# CH32M030 register map
Vendor: WCH Ltd.; File version: 1.1
Registers are 32-bit, read-write, reset 0x0 unless marked. A register's access mark holds for its fields unless they carry their own. Offsets are from the block's base; [hi:lo] are bit positions.

## WWDG — Window watchdog
Base 0x40002C00
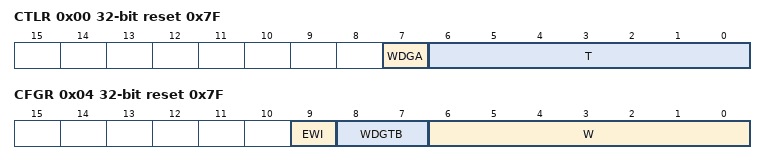
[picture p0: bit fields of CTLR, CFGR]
0x00 CTLR reset 0x7F — Control register (WWDG_CR)
  [7] WDGA — Activation bit
  [6:0] T — 7-bit counter (MSB to LSB)
0x04 CFGR reset 0x7F — Configuration register (WWDG_CFR)
  [9] EWI — Early Wakeup Interrupt
  [8:7] WDGTB — Timer Base
  [6:0] W — 7-bit window value
0x08 STATR — Status register (WWDG_SR)
  [0] EWIF — Early Wakeup Interrupt Flag

## TIM3 — Streamlined Timer
Base 0x40000400
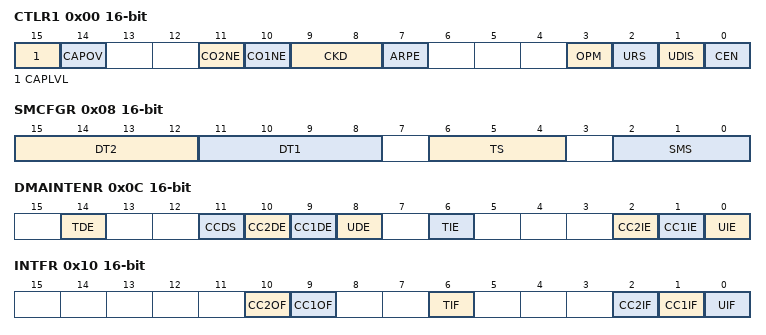
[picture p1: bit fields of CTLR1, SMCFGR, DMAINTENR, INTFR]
0x00 CTLR1 16-bit — control register 1
  [15] CAPLVL — Timer capture level indication enable
  [14] CAPOV — Timer capture value configuration enable
  [11] CO2NE — complementary output with dead zone enabled
  [10] CO1NE — complementary output with dead zone enabled
  [9:8] CKD — Clock division
  [7] ARPE — Auto-reload preload enable
  [3] OPM — One-pulse mode
  [2] URS — Update request source
  [1] UDIS — Update disable
  [0] CEN — Counter enable
0x08 SMCFGR 16-bit — slave mode control register
  [15:12] DT2 — TIMER3 channel2 dead-time setting
  [11:8] DT1 — TIMER3 channel1 dead-time setting
  [6:4] TS — Trigger selection
  [2:0] SMS — Slave mode selection
0x0C DMAINTENR 16-bit — DMA/Interrupt enable register
  [14] TDE — Trigger DMA request enable
  [11] CCDS — Capture/compare DMA selection
  [10] CC2DE — Capture/Compare 2 DMA request enable
  [9] CC1DE — Capture/Compare 1 DMA request enable
  [8] UDE — Update DMA request enable
  [6] TIE — Trigger interrupt enable
  [2] CC2IE — Capture/Compare 2 interrupt enable
  [1] CC1IE — Capture/Compare 1 interrupt enable
  [0] UIE — Update interrupt enable
0x10 INTFR 16-bit — status register
  [10] CC2OF — Capture/compare 2 overcapture flag
  [9] CC1OF — Capture/Compare 1 overcapture flag
  [6] TIF — Trigger interrupt flag
  [2] CC2IF — Capture/Compare 2 interrupt flag
  [1] CC1IF — Capture/compare 1 interrupt flag
  [0] UIF — Update interrupt flag
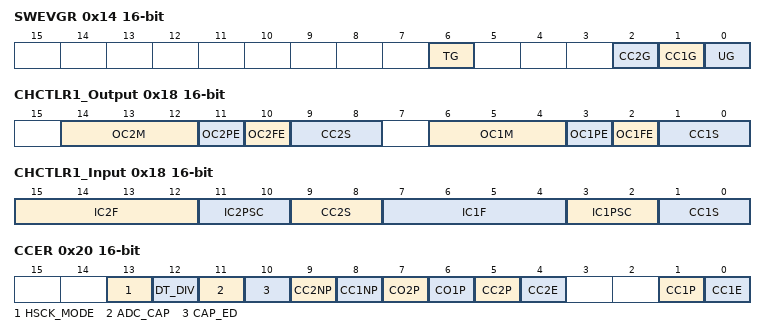
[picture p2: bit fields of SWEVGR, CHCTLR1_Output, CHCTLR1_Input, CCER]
0x14 SWEVGR 16-bit wo — event generation register
  [6] TG — Trigger generation
  [2] CC2G — Capture/compare 2 generation
  [1] CC1G — Capture/compare 1 generation
  [0] UG — Update generation
0x18 CHCTLR1_Output 16-bit — capture/compare mode register 1 (output mode)
  [14:12] OC2M — Output compare channel 2 mode
  [11] OC2PE — Compare capture register 1 preload enable
  [10] OC2FE — Output compare channel 2 fast enable
  [9:8] CC2S — Capture/Compare channel 2 input selection
  [6:4] OC1M — Output compare 1 mode
  [3] OC1PE — Output compare 1 preload enable
  [2] OC1FE — Output compare 1 fast enable
  [1:0] CC1S — Capture/Compare 1 selection
0x18 CHCTLR1_Input 16-bit (alternate view of CHCTLR1_Output) — capture/compare mode register 1 (input mode)
  [15:12] IC2F — Input capture 2 filter
  [11:10] IC2PSC — Input capture 2 prescaler
  [9:8] CC2S — Capture/compare 2 selection
  [7:4] IC1F — Input capture 1 filter
  [3:2] IC1PSC — Input capture 1 prescaler
  [1:0] CC1S — Capture/Compare 1 selection
0x20 CCER 16-bit — capture/compare enable register
  [13] HSCK_MODE — counter clock is selected to enable the PLL clock
  [12] DT_DIV — dead-time counts clock frequency division
  [11] ADC_CAP — capture the ADC module signal edge function enabled
  [10] CAP_ED — Double-side egde capture is enable for channel2
  [9] CC2NP — Channel2 cpmplementary output Polarity setting
  [8] CC1NP — Channel1 cpmplementary output Polarity setting
  [7] CO2P — Channel2 output Polarity setting
  [6] CO1P — Channel2 output Polarity setting
  [5] CC2P — Capture/Compare 2 output Polarity
  [4] CC2E — Capture/Compare 2 output enable
  [1] CC1P — Capture/Compare 1 output Polarity
  [0] CC1E — Capture/Compare 1 output enable
0x24 CNT — counter
  [15:0] CNT — counter value
0x28 PSC — prescaler
  [15:0] PSC — Prescaler value
0x2C ATRLR reset 0xFFFF — auto-reload register
  [15:0] ATRLR — Auto-reload value
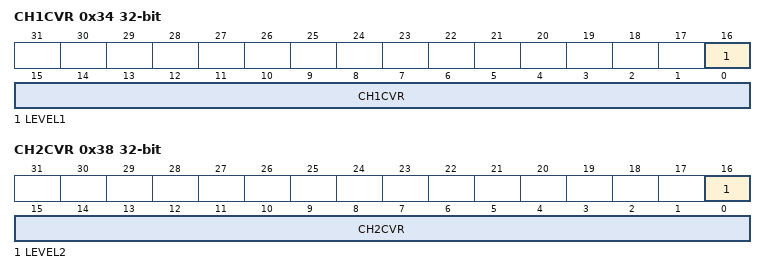
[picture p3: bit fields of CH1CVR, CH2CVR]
0x34 CH1CVR — capture/compare register 1
  [16] LEVEL1 — Level indicating bit
  [15:0] CH1CVR — Capture/Compare 1 value
0x38 CH2CVR — capture/compare register 2
  [16] LEVEL2 — Level indicating bit
  [15:0] CH2CVR — Capture/Compare 2 value
